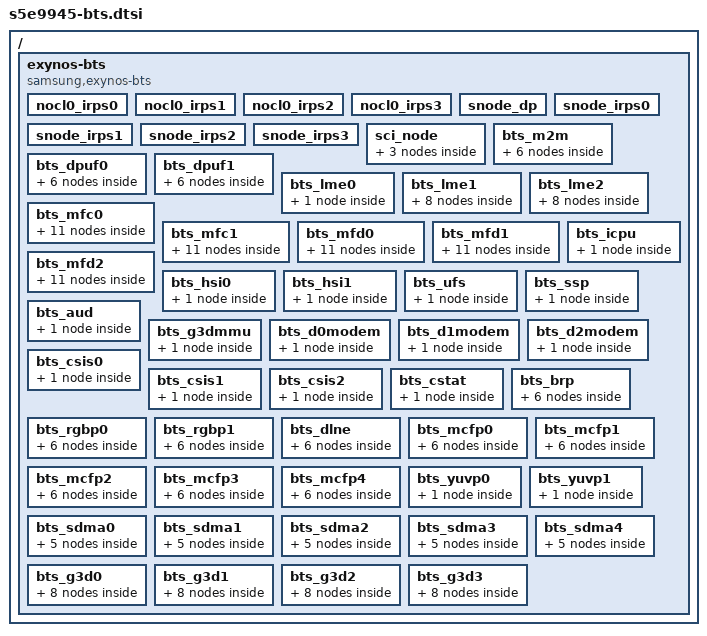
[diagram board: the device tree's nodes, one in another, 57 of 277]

/* SAMSUNG EXYNOS SoC BTS device tree source
 *
 * Copyright (c) 2018 Samsung Electronics Co., Ltd.
 *		http://www.samsung.com
 *
 * SAMSUNG EXYNOS SoC BTS device nodes are listed in this file.
 * EXYNOS based board files should include this file.
 *
 * This program is free software; you can redistribute it and/or modify
 * it under the terms of the GNU General Public License version 2 as
 * published by the Free Software Foundation.
 *
 */

#include <dt-bindings/soc/samsung/exynos-bts.h>

/*
 * TREX_D_NOCL0		0x229E0000
 * TREX_D_NOCL1A	0x238E0000
 * TREX_D_NOCL1B	0x24880000
 * TREX_D_NOCL2A	0x258E0000
 * TREX_D_SDMA		0x213F0000
 * SCI				0x22800000
 * SYSREG_NOCL0		0x22820000
 */

/ {
	exynos-bts {
		compatible = "samsung,exynos-bts";
		acpm-ipc-channel = <8>;
		vch_pd_calid = <0xB1380002>;
		#address-cells = <2>;
		#size-cells = <1>;
		ranges;

		list-scen = "default",
			"cp_throughput",
			"mfc_uhd",
			"mfc_uhd_10bit",
			"mfc_8k_dec30",
			"gdc_8k_8b_30",
			"gdc_8k_8b_60",
			"g3d_heavy",
			"g3d_performance",
			"dp_default",
			"camera_default",
			"npu_normal",
			"mfc_uhd_enc60",
			"camera_heavy",
			"npu_performance";

	        /* num_channel, mif_bus_width, bus_width, mif_util, int_util*/
	        bw_params = <4 16 32 70 70>;

		/* IRPS0/1/2/3 SCI_CTL_SCI_CTRL*/
		nocl0_irps0 {
			#address-cells = <2>;
			#size-cells = <1>;
			ranges;
			reg = <0x0 0x229EA000 0x40>;
			status = "okay";
			bts-type = <TREX_BTS>;
		};
		nocl0_irps1 {
			reg = <0x0 0x229EA040 0x40>;
			status = "okay";
			bts-type = <TREX_BTS>;
		};
		nocl0_irps2 {
			reg = <0x0 0x229EA080 0x40>;
			status = "okay";
			bts-type = <TREX_BTS>;
		};
		nocl0_irps3 {
			reg = <0x0 0x229EA0C0 0x40>;
			status = "okay";
			bts-type = <TREX_BTS>;
		};
		/* QMAX THRESHOLD */
		snode_dp {
			reg = <0x0 0x229EB040 0x8>;
			status = "okay";
			bts-type = <BUSC_BTS>;
		};
		snode_irps0 {
			reg = <0x0 0x229EB000 0x8>;
			status = "okay";
			bts-type = <BUSC_BTS>;
		};
		snode_irps1 {
			reg = <0x0 0x229EB010 0x8>;
			status = "okay";
			bts-type = <BUSC_BTS>;
		};
		snode_irps2 {
			reg = <0x0 0x229EB020 0x8>;
			status = "okay";
			bts-type = <BUSC_BTS>;
		};
		snode_irps3 {
			reg = <0x0 0x229EB030 0x8>;
			status = "okay";
			bts-type = <BUSC_BTS>;
		};
		sci_node {
			reg = <0x0 0x22800100 0x100>;
			status = "okay";
			bts-type = <SCI_BTS>;
			default {
				stat_on = <1>;
				rmo = <0x0>;
				wmo = <0x0>;
				hurrylevel3mo_0 = <0x88>;
				hurrylevel3mo_1 = <0x88>;
			};
			camera_default {
				stat_on = <1>;
				rmo = <0x8>;
				wmo = <0x8>;
				hurrylevel3mo_0 = <0x88>;
				hurrylevel3mo_1 = <0x88>;
			};
			camera_heavy {
				stat_on = <1>;
				rmo = <0x8>;
				wmo = <0x8>;
				hurrylevel3mo_0 = <0x88>;
				hurrylevel3mo_1 = <0x88>;
			};
		};
		/* NOCL1A M2M */
		bts_m2m {
			reg = <0x0 0x238E8000 0x80>;
			status = "okay";
			bts-type = <IP_BTS>;
			default {
				stat_on = <1>;
				bypass = <0>;
				arqos = <0x4>;
				awqos = <0x4>;
				rmo = <0x18>;
				wmo = <0x18>;
				qurgent_on = <0>;
				blocking_on = <1>;
				qmax0_limit_r = <0x8>;
				qmax0_limit_w = <0x8>;
			};
			camera_default {
				stat_on = <1>;
				bypass = <0>;
				arqos = <0x4>;
				awqos = <0x4>;
				rmo = <0x8>;
				wmo = <0x8>;
				qurgent_on = <0>;
				blocking_on = <0>;
			};
			npu_normal {
				stat_on = <1>;
				bypass = <0>;
				arqos = <0x4>;
				awqos = <0x4>;
				rmo = <0x8>;
				wmo = <0x8>;
				qurgent_on = <0>;
				blocking_on = <0>;
			};
			mfc_uhd_enc60 {
				stat_on = <1>;
				bypass = <0>;
				arqos = <0x4>;
				awqos = <0x4>;
				rmo = <0x8>;
				wmo = <0x8>;
				qurgent_on = <0>;
				blocking_on = <0>;
			};
			camera_heavy {
				stat_on = <1>;
				bypass = <0>;
				arqos = <0x4>;
				awqos = <0x4>;
				rmo = <0x20>;
				wmo = <0x20>;
				qurgent_on = <0>;
				blocking_on = <0>;
			};
			npu_performance {
				stat_on = <1>;
				bypass = <0>;
				arqos = <0x4>;
				awqos = <0x4>;
				rmo = <0x8>;
				wmo = <0x8>;
				qurgent_on = <0>;
				blocking_on = <0>;
			};
		};
		/* NOCL1A D0_DPUF0 */
		bts_dpuf0 {
			reg = <0x0 0x238E8080 0x80>;
			status = "okay";
			bts-type = <IP_BTS>;
			default {
				stat_on = <1>;
				bypass = <0>;
				arqos = <0x8>;
				awqos = <0xF>;
				qurgent_on = <0x1>;
				qurgent_th_r = <0x14>;
				blocking_on = <0>;
			};
			camera_default {
				stat_on = <1>;
				bypass = <0>;
				arqos = <0x8>;
				awqos = <0xF>;
				rmo = <0x30>;
				wmo = <0x30>;
				qurgent_on = <0x1>;
				qurgent_th_r = <0x14>;
				blocking_on = <0>;
			};
			npu_normal {
				stat_on = <1>;
				bypass = <0>;
				arqos = <0x8>;
				awqos = <0xF>;
				rmo = <0x30>;
				wmo = <0x30>;
				qurgent_on = <0x1>;
				qurgent_th_r = <0x14>;
				blocking_on = <0>;
			};
			mfc_uhd_enc60 {
				stat_on = <1>;
				bypass = <0>;
				arqos = <0x8>;
				awqos = <0xF>;
				rmo = <0x20>;
				wmo = <0x20>;
				qurgent_on = <0>;
				blocking_on = <0>;
			};
			camera_heavy {
				stat_on = <1>;
				bypass = <0>;
				arqos = <0x8>;
				awqos = <0xF>;
				rmo = <0x30>;
				wmo = <0x30>;
				qurgent_on = <0x1>;
				qurgent_th_r = <0x14>;
				blocking_on = <0>;
			};
			npu_performance {
				stat_on = <1>;
				bypass = <0>;
				arqos = <0x8>;
				awqos = <0xF>;
				rmo = <0x20>;
				wmo = <0x20>;
				qurgent_on = <0>;
				blocking_on = <0>;
			};
		};
		/* NOCL1A D1_DPUF0 */
		bts_dpuf1 {
			reg = <0x0 0x238E8100 0x80>;
			status = "okay";
			bts-type = <IP_BTS>;
			default {
				stat_on = <1>;
				bypass = <0>;
				arqos = <0x8>;
				awqos = <0xF>;
				qurgent_on = <0x1>;
				qurgent_th_r = <0x14>;
				blocking_on = <0>;
			};
			camera_default {
				stat_on = <1>;
				bypass = <0>;
				arqos = <0x8>;
				awqos = <0xF>;
				rmo = <0x30>;
				wmo = <0x30>;
				qurgent_on = <0x1>;
				qurgent_th_r = <0x14>;
				blocking_on = <0>;
			};
			npu_normal {
				stat_on = <1>;
				bypass = <0>;
				arqos = <0x8>;
				awqos = <0xF>;
				rmo = <0x30>;
				wmo = <0x30>;
				qurgent_on = <0x1>;
				qurgent_th_r = <0x14>;
				blocking_on = <0>;
			};
			mfc_uhd_enc60 {
				stat_on = <1>;
				bypass = <0>;
				arqos = <0x8>;
				awqos = <0xF>;
				rmo = <0x20>;
				wmo = <0x20>;
				qurgent_on = <0>;
				blocking_on = <0>;
			};
			camera_heavy {
				stat_on = <1>;
				bypass = <0>;
				arqos = <0x8>;
				awqos = <0xF>;
				rmo = <0x30>;
				wmo = <0x30>;
				qurgent_on = <0x1>;
				qurgent_th_r = <0x14>;
				blocking_on = <0>;
			};
			npu_performance {
				stat_on = <1>;
				bypass = <0>;
				arqos = <0x8>;
				awqos = <0xF>;
				rmo = <0x20>;
				wmo = <0x20>;
				qurgent_on = <0>;
				blocking_on = <0>;
			};
		};
		/* NOCL1A D0LME */
		bts_lme0 {
			reg = <0x0 0x238E8180 0x80>;
			status = "okay";
			bts-type = <IP_BTS>;
			default {
				stat_on = <1>;
				bypass = <0>;
				arqos = <0x4>;
				awqos = <0x4>;
				rmo = <0x14>;
				wmo = <0x10>;
				qurgent_on = <0>;
				blocking_on = <0>;
			};
		};
		/* NOCL1A D1LME */
		bts_lme1 {
			reg = <0x0 0x238E8200 0x80>;
			status = "okay";
			bts-type = <IP_BTS>;
			default {
				stat_on = <1>;
				bypass = <0>;
				arqos = <0x4>;
				awqos = <0x4>;
				rmo = <0x4>;
				wmo = <0x8>;
				qurgent_on = <0>;
				blocking_on = <0>;
			};
			gdc_8k_8b_30 {
				stat_on = <1>;
				bypass = <0>;
				arqos = <0x4>;
				awqos = <0x4>;
				rmo = <0x3C>;
				wmo = <0x14>;
				qurgent_on = <0>;
				blocking_on = <0>;
			};
			gdc_8k_8b_60 {
				stat_on = <1>;
				bypass = <0>;
				arqos = <0x4>;
				awqos = <0x4>;
				rmo = <0x84>;
				wmo = <0x28>;
				qurgent_on = <0>;
				blocking_on = <0>;
			};
			camera_default {
				stat_on = <1>;
				bypass = <0>;
				arqos = <0x4>;
				awqos = <0x4>;
				rmo = <0x14>;
				wmo = <0x8>;
				qurgent_on = <0>;
				blocking_on = <0>;
			};
			npu_normal {
				stat_on = <1>;
				bypass = <0>;
				arqos = <0x4>;
				awqos = <0x4>;
				rmo = <0x14>;
				wmo = <0x8>;
				qurgent_on = <0>;
				blocking_on = <0>;
			};
			mfc_uhd_enc60 {
				stat_on = <1>;
				bypass = <0>;
				arqos = <0x4>;
				awqos = <0x4>;
				rmo = <0x14>;
				wmo = <0x8>;
				qurgent_on = <0>;
				blocking_on = <0>;
			};
			camera_heavy {
				stat_on = <1>;
				bypass = <0>;
				arqos = <0x4>;
				awqos = <0x4>;
				rmo = <0x28>;
				wmo = <0x10>;
				qurgent_on = <0>;
				blocking_on = <0>;
			};
			npu_performance {
				stat_on = <1>;
				bypass = <0>;
				arqos = <0x4>;
				awqos = <0x4>;
				rmo = <0x4>;
				wmo = <0x8>;
				qurgent_on = <0>;
				blocking_on = <0>;
			};
		};
		/* NOCL1A D2LME */
		bts_lme2 {
			reg = <0x0 0x238E8280 0x80>;
			status = "okay";
			bts-type = <IP_BTS>;
			default {
				stat_on = <1>;
				bypass = <0>;
				arqos = <0x4>;
				awqos = <0x4>;
				rmo = <0xC>;
				wmo = <0xC>;
				qurgent_on = <0>;
				blocking_on = <0>;
			};
			gdc_8k_8b_30 {
				stat_on = <1>;
				bypass = <0>;
				arqos = <0x4>;
				awqos = <0x4>;
				rmo = <0xC>;
				wmo = <0xC>;
				qurgent_on = <0>;
				blocking_on = <0>;
			};
			gdc_8k_8b_60 {
				stat_on = <1>;
				bypass = <0>;
				arqos = <0x4>;
				awqos = <0x4>;
				rmo = <0xC>;
				wmo = <0xC>;
				qurgent_on = <0>;
				blocking_on = <0>;
			};
			camera_default {
				stat_on = <1>;
				bypass = <0>;
				arqos = <0x4>;
				awqos = <0x4>;
				rmo = <0xC>;
				wmo = <0xC>;
				qurgent_on = <0>;
				blocking_on = <0>;
			};
			npu_normal {
				stat_on = <1>;
				bypass = <0>;
				arqos = <0x4>;
				awqos = <0x4>;
				rmo = <0xC>;
				wmo = <0xC>;
				qurgent_on = <0>;
				blocking_on = <0>;
			};
			mfc_uhd_enc60 {
				stat_on = <1>;
				bypass = <0>;
				arqos = <0x4>;
				awqos = <0x4>;
				rmo = <0xC>;
				wmo = <0xC>;
				qurgent_on = <0>;
				blocking_on = <0>;
			};
			camera_heavy {
				stat_on = <1>;
				bypass = <0>;
				arqos = <0x4>;
				awqos = <0x4>;
				rmo = <0xE>;
				wmo = <0xE>;
				qurgent_on = <0>;
				blocking_on = <0>;
			};
			npu_performance {
				stat_on = <1>;
				bypass = <0>;
				arqos = <0x4>;
				awqos = <0x4>;
				rmo = <0xC>;
				wmo = <0xC>;
				qurgent_on = <0>;
				blocking_on = <0>;
			};
		};
		/* NOCL1B D0_MFC */
		bts_mfc0 {
			reg = <0x0 0x24888000 0x80>;
			status = "okay";
			bts-type = <IP_BTS>;
			default {
				stat_on = <1>;
				bypass = <0>;
				arqos = <0x4>;
				awqos = <0x4>;
				rmo = <0x1C>;
				wmo = <0xC>;
				qurgent_on = <0>;
				blocking_on = <0>;
			};
			mfc_uhd {
				stat_on = <1>;
				bypass = <0>;
				arqos = <0x4>;
				awqos = <0x4>;
				rmo = <0x20>;
				wmo = <0x20>;
				qurgent_on = <0>;
				blocking_on = <0>;
			};
			mfc_uhd_10bit {
				stat_on = <1>;
				bypass = <0>;
				arqos = <0x4>;
				awqos = <0x4>;
				rmo = <0x20>;
				wmo = <0x20>;
				qurgent_on = <0>;
				blocking_on = <0>;
			};
			mfc_8k_dec30 {
				stat_on = <1>;
				bypass = <0>;
				arqos = <0x4>;
				awqos = <0x4>;
				rmo = <0x40>;
				wmo = <0x40>;
				qurgent_on = <0>;
				blocking_on = <0>;
			};
			g3d_performance {
				stat_on = <1>;
				bypass = <0>;
				arqos = <0x4>;
				awqos = <0x4>;
				rmo = <0x20>;
				wmo = <0x20>;
				qurgent_on = <0>;
				blocking_on = <0>;
			};
			dp_default {
				stat_on = <1>;
				bypass = <0>;
				arqos = <0x4>;
				awqos = <0x4>;
				rmo = <0x20>;
				wmo = <0x20>;
				qurgent_on = <0>;
				blocking_on = <0>;
			};
			camera_default {
				stat_on = <1>;
				bypass = <0>;
				arqos = <0x4>;
				awqos = <0x4>;
				rmo = <0x1C>;
				wmo = <0xC>;
				qurgent_on = <0>;
				blocking_on = <0>;
			};
			npu_normal {
				stat_on = <1>;
				bypass = <0>;
				arqos = <0x4>;
				awqos = <0x4>;
				rmo = <0x1C>;
				wmo = <0xC>;
				qurgent_on = <0>;
				blocking_on = <0>;
			};
			mfc_uhd_enc60 {
				stat_on = <1>;
				bypass = <0>;
				arqos = <0x4>;
				awqos = <0x4>;
				rmo = <0x20>;
				wmo = <0x20>;
				qurgent_on = <0>;
				blocking_on = <0>;
			};
			camera_heavy {
				stat_on = <1>;
				bypass = <0>;
				arqos = <0x4>;
				awqos = <0x4>;
				rmo = <0x1C>;
				wmo = <0xC>;
				qurgent_on = <0>;
				blocking_on = <0>;
			};
			npu_performance {
				stat_on = <1>;
				bypass = <0>;
				arqos = <0x4>;
				awqos = <0x4>;
				rmo = <0x1C>;
				wmo = <0xC>;
				qurgent_on = <0>;
				blocking_on = <0>;
			};
		};
		/* NOCL1B D1_MFC */
		bts_mfc1 {
			reg = <0x0 0x24888080 0x80>;
			status = "okay";
			bts-type = <IP_BTS>;
			default {
				stat_on = <1>;
				bypass = <0>;
				arqos = <0x4>;
				awqos = <0x4>;
				rmo = <0x1C>;
				wmo = <0xC>;
				qurgent_on = <0>;
				blocking_on = <0>;
			};
			mfc_uhd {
				stat_on = <1>;
				bypass = <0>;
				arqos = <0x4>;
				awqos = <0x4>;
				rmo = <0x20>;
				wmo = <0x20>;
				qurgent_on = <0>;
				blocking_on = <0>;
			};
			mfc_uhd_10bit {
				stat_on = <1>;
				bypass = <0>;
				arqos = <0x4>;
				awqos = <0x4>;
				rmo = <0x20>;
				wmo = <0x20>;
				qurgent_on = <0>;
				blocking_on = <0>;
			};
			mfc_8k_dec30 {
				stat_on = <1>;
				bypass = <0>;
				arqos = <0x4>;
				awqos = <0x4>;
				rmo = <0x40>;
				wmo = <0x40>;
				qurgent_on = <0>;
				blocking_on = <0>;
			};
			g3d_performance {
				stat_on = <1>;
				bypass = <0>;
				arqos = <0x4>;
				awqos = <0x4>;
				rmo = <0x20>;
				wmo = <0x20>;
				qurgent_on = <0>;
				blocking_on = <0>;
			};
			dp_default {
				stat_on = <1>;
				bypass = <0>;
				arqos = <0x4>;
				awqos = <0x4>;
				rmo = <0x20>;
				wmo = <0x20>;
				qurgent_on = <0>;
				blocking_on = <0>;
			};
			camera_default {
				stat_on = <1>;
				bypass = <0>;
				arqos = <0x4>;
				awqos = <0x4>;
				rmo = <0x1C>;
				wmo = <0xC>;
				qurgent_on = <0>;
				blocking_on = <0>;
			};
			npu_normal {
				stat_on = <1>;
				bypass = <0>;
				arqos = <0x4>;
				awqos = <0x4>;
				rmo = <0x1C>;
				wmo = <0xC>;
				qurgent_on = <0>;
				blocking_on = <0>;
			};
			mfc_uhd_enc60 {
				stat_on = <1>;
				bypass = <0>;
				arqos = <0x4>;
				awqos = <0x4>;
				rmo = <0x20>;
				wmo = <0x20>;
				qurgent_on = <0>;
				blocking_on = <0>;
			};
			camera_heavy {
				stat_on = <1>;
				bypass = <0>;
				arqos = <0x4>;
				awqos = <0x4>;
				rmo = <0x1C>;
				wmo = <0xC>;
				qurgent_on = <0>;
				blocking_on = <0>;
			};
			npu_performance {
				stat_on = <1>;
				bypass = <0>;
				arqos = <0x4>;
				awqos = <0x4>;
				rmo = <0x1C>;
				wmo = <0xC>;
				qurgent_on = <0>;
				blocking_on = <0>;
			};
		};
		/* NOCL1B D0_MFD */
		bts_mfd0 {
			reg = <0x0 0x24888100 0x80>;
			status = "okay";
			bts-type = <IP_BTS>;
			default {
				stat_on = <1>;
				bypass = <0>;
				arqos = <0x4>;
				awqos = <0x4>;
				rmo = <0x1C>;
				wmo = <0xC>;
				qurgent_on = <0>;
				blocking_on = <0>;
			};
			mfc_uhd {
				stat_on = <1>;
				bypass = <0>;
				arqos = <0x4>;
				awqos = <0x4>;
				rmo = <0x20>;
				wmo = <0x20>;
				qurgent_on = <0>;
				blocking_on = <0>;
			};
			mfc_uhd_10bit {
				stat_on = <1>;
				bypass = <0>;
				arqos = <0x4>;
				awqos = <0x4>;
				rmo = <0x20>;
				wmo = <0x20>;
				qurgent_on = <0>;
				blocking_on = <0>;
			};
			mfc_8k_dec30 {
				stat_on = <1>;
				bypass = <0>;
				arqos = <0x4>;
				awqos = <0x4>;
				rmo = <0x40>;
				wmo = <0x40>;
				qurgent_on = <0>;
				blocking_on = <0>;
			};
			g3d_performance {
				stat_on = <1>;
				bypass = <0>;
				arqos = <0x4>;
				awqos = <0x4>;
				rmo = <0x20>;
				wmo = <0x20>;
				qurgent_on = <0>;
				blocking_on = <0>;
			};
			dp_default {
				stat_on = <1>;
				bypass = <0>;
				arqos = <0x4>;
				awqos = <0x4>;
				rmo = <0x20>;
				wmo = <0x20>;
				qurgent_on = <0>;
				blocking_on = <0>;
			};
			camera_default {
				stat_on = <1>;
				bypass = <0>;
				arqos = <0x4>;
				awqos = <0x4>;
				rmo = <0x1C>;
				wmo = <0xC>;
				qurgent_on = <0>;
				blocking_on = <0>;
			};
			npu_normal {
				stat_on = <1>;
				bypass = <0>;
				arqos = <0x4>;
				awqos = <0x4>;
				rmo = <0x1C>;
				wmo = <0xC>;
				qurgent_on = <0>;
				blocking_on = <0>;
			};
			mfc_uhd_enc60 {
				stat_on = <1>;
				bypass = <0>;
				arqos = <0x4>;
				awqos = <0x4>;
				rmo = <0x20>;
				wmo = <0x20>;
				qurgent_on = <0>;
				blocking_on = <0>;
			};
			camera_heavy {
				stat_on = <1>;
				bypass = <0>;
				arqos = <0x4>;
				awqos = <0x4>;
				rmo = <0x1C>;
				wmo = <0xC>;
				qurgent_on = <0>;
				blocking_on = <0>;
			};
			npu_performance {
				stat_on = <1>;
				bypass = <0>;
				arqos = <0x4>;
				awqos = <0x4>;
				rmo = <0x20>;
				wmo = <0x20>;
				qurgent_on = <0>;
				blocking_on = <0>;
			};
		};
		/* NOCL1B D1_MFD */
		bts_mfd1 {
			reg = <0x0 0x24888180 0x80>;
			status = "okay";
			bts-type = <IP_BTS>;
			default {
				stat_on = <1>;
				bypass = <0>;
				arqos = <0x4>;
				awqos = <0x4>;
				rmo = <0x1C>;
				wmo = <0xC>;
				qurgent_on = <0>;
				blocking_on = <0>;
			};
			mfc_uhd {
				stat_on = <1>;
				bypass = <0>;
				arqos = <0x4>;
				awqos = <0x4>;
				rmo = <0x20>;
				wmo = <0x20>;
				qurgent_on = <0>;
				blocking_on = <0>;
			};
			mfc_uhd_10bit {
				stat_on = <1>;
				bypass = <0>;
				arqos = <0x4>;
				awqos = <0x4>;
				rmo = <0x20>;
				wmo = <0x20>;
				qurgent_on = <0>;
				blocking_on = <0>;
			};
			mfc_8k_dec30 {
				stat_on = <1>;
				bypass = <0>;
				arqos = <0x4>;
				awqos = <0x4>;
				rmo = <0x40>;
				wmo = <0x40>;
				qurgent_on = <0>;
				blocking_on = <0>;
			};
			g3d_performance {
				stat_on = <1>;
				bypass = <0>;
				arqos = <0x4>;
				awqos = <0x4>;
				rmo = <0x20>;
				wmo = <0x20>;
				qurgent_on = <0>;
				blocking_on = <0>;
			};
			dp_default {
				stat_on = <1>;
				bypass = <0>;
				arqos = <0x4>;
				awqos = <0x4>;
				rmo = <0x20>;
				wmo = <0x20>;
				qurgent_on = <0>;
				blocking_on = <0>;
			};
			camera_default {
				stat_on = <1>;
				bypass = <0>;
				arqos = <0x4>;
				awqos = <0x4>;
				rmo = <0x1C>;
				wmo = <0xC>;
				qurgent_on = <0>;
				blocking_on = <0>;
			};
			npu_normal {
				stat_on = <1>;
				bypass = <0>;
				arqos = <0x4>;
				awqos = <0x4>;
				rmo = <0x1C>;
				wmo = <0xC>;
				qurgent_on = <0>;
				blocking_on = <0>;
			};
			mfc_uhd_enc60 {
				stat_on = <1>;
				bypass = <0>;
				arqos = <0x4>;
				awqos = <0x4>;
				rmo = <0x20>;
				wmo = <0x20>;
				qurgent_on = <0>;
				blocking_on = <0>;
			};
			camera_heavy {
				stat_on = <1>;
				bypass = <0>;
				arqos = <0x4>;
				awqos = <0x4>;
				rmo = <0x1C>;
				wmo = <0xC>;
				qurgent_on = <0>;
				blocking_on = <0>;
			};
			npu_performance {
				stat_on = <1>;
				bypass = <0>;
				arqos = <0x4>;
				awqos = <0x4>;
				rmo = <0x1C>;
				wmo = <0xC>;
				qurgent_on = <0>;
				blocking_on = <0>;
			};
		};
		/* NOCL1B D2_MFD */
		bts_mfd2 {
			reg = <0x0 0x24888200 0x80>;
			status = "okay";
			bts-type = <IP_BTS>;
			default {
				stat_on = <1>;
				bypass = <0>;
				arqos = <0x4>;
				awqos = <0x4>;
				rmo = <0x1C>;
				wmo = <0xC>;
				qurgent_on = <0>;
				blocking_on = <0>;
			};
			mfc_uhd {
				stat_on = <1>;
				bypass = <0>;
				arqos = <0x4>;
				awqos = <0x4>;
				rmo = <0x20>;
				wmo = <0x20>;
				qurgent_on = <0>;
				blocking_on = <0>;
			};
			mfc_uhd_10bit {
				stat_on = <1>;
				bypass = <0>;
				arqos = <0x4>;
				awqos = <0x4>;
				rmo = <0x20>;
				wmo = <0x20>;
				qurgent_on = <0>;
				blocking_on = <0>;
			};
			mfc_8k_dec30 {
				stat_on = <1>;
				bypass = <0>;
				arqos = <0x4>;
				awqos = <0x4>;
				rmo = <0x40>;
				wmo = <0x40>;
				qurgent_on = <0>;
				blocking_on = <0>;
			};
			g3d_performance {
				stat_on = <1>;
				bypass = <0>;
				arqos = <0x4>;
				awqos = <0x4>;
				rmo = <0x20>;
				wmo = <0x20>;
				qurgent_on = <0>;
				blocking_on = <0>;
			};
			dp_default {
				stat_on = <1>;
				bypass = <0>;
				arqos = <0x4>;
				awqos = <0x4>;
				rmo = <0x20>;
				wmo = <0x20>;
				qurgent_on = <0>;
				blocking_on = <0>;
			};
			camera_default {
				stat_on = <1>;
				bypass = <0>;
				arqos = <0x4>;
				awqos = <0x4>;
				rmo = <0x1C>;
				wmo = <0xC>;
				qurgent_on = <0>;
				blocking_on = <0>;
			};
			npu_normal {
				stat_on = <1>;
				bypass = <0>;
				arqos = <0x4>;
				awqos = <0x4>;
				rmo = <0x1C>;
				wmo = <0xC>;
				qurgent_on = <0>;
				blocking_on = <0>;
			};
			mfc_uhd_enc60 {
				stat_on = <1>;
				bypass = <0>;
				arqos = <0x4>;
				awqos = <0x4>;
				rmo = <0x20>;
				wmo = <0x20>;
				qurgent_on = <0>;
				blocking_on = <0>;
			};
			camera_heavy {
				stat_on = <1>;
				bypass = <0>;
				arqos = <0x4>;
				awqos = <0x4>;
				rmo = <0x1C>;
				wmo = <0xC>;
				qurgent_on = <0>;
				blocking_on = <0>;
			};
			npu_performance {
				stat_on = <1>;
				bypass = <0>;
				arqos = <0x4>;
				awqos = <0x4>;
				rmo = <0x1C>;
				wmo = <0xC>;
				qurgent_on = <0>;
				blocking_on = <0>;
			};
		};
		/* NOCL1B ICPU */
		bts_icpu {
			reg = <0x0 0x24888280 0x80>;
			status = "okay";
			bts-type = <IP_BTS>;
			cal-pdid = <0xB1380002>;
			default {
				stat_on = <1>;
				bypass = <0>;
				arqos = <0x4>;
				awqos = <0x4>;
				rmo = <0xFFFF>;
				wmo = <0xFFFF>;
				qurgent_on = <0>;
				blocking_on = <0>;
			};
		};
		/* NOCL1B HSI0 */
		bts_hsi0 {
			reg = <0x0 0x24888300 0x80>;
			status = "okay";
			bts-type = <IP_BTS>;
			default {
				stat_on = <1>;
				bypass = <0>;
				arqos = <0x4>;
				awqos = <0x4>;
				rmo = <0x4>;
				wmo = <0x4>;
				qurgent_on = <0>;
				blocking_on = <1>;
				qmax0_limit_r = <0x1>;
				qmax0_limit_w = <0x1>;
			};
		};
		/* NOCL1B HSI1 */
		bts_hsi1 {
			reg = <0x0 0x24888380 0x80>;
			status = "okay";
			bts-type = <IP_BTS>;
			default {
				stat_on = <1>;
				bypass = <0>;
				arqos = <0x4>;
				awqos = <0x4>;
				rmo = <0x8>;
				wmo = <0x8>;
				qurgent_on = <0>;
				blocking_on = <1>;
				qmax0_limit_r = <0x1>;
				qmax0_limit_w = <0x1>;
			};
		};
		/* NOCL1B ufs */
		bts_ufs {
			reg = <0x0 0x24888400 0x80>;
			status = "okay";
			bts-type = <IP_BTS>;
			default {
				stat_on = <1>;
				bypass = <0>;
				arqos = <0x4>;
				awqos = <0x4>;
				rmo = <0x10>;
				wmo = <0xC>;
				qurgent_on = <0>;
				blocking_on = <1>;
				qmax0_limit_r = <0x1>;
				qmax0_limit_w = <0x1>;
			};
		};
		/* NOCL1B SSP */
		bts_ssp {
			reg = <0x0 0x24888480 0x80>;
			status = "okay";
			bts-type = <IP_BTS>;
			default {
				stat_on = <1>;
				bypass = <0>;
				arqos = <0x4>;
				awqos = <0x4>;
				rmo = <0x4>;
				wmo = <0x4>;
				qurgent_on = <0>;
				blocking_on = <0>;
			};
		};
		/* NOCL1A AUD */
		bts_aud {
			reg = <0x0 0x238E8300 0x80>;
			status = "okay";
			bts-type = <IP_BTS>;
			default {
				stat_on = <1>;
				bypass = <0>;
				arqos = <0xC>;
				awqos = <0xF>;
				qurgent_on = <0x1>;
				qurgent_th_r = <0x14>;
				qurgent_th_w = <0x14>;
				blocking_on = <0>;
			};
		};
		/* NOCL0 MMUCS */
		bts_g3dmmu {
			reg = <0x0 0x229E8200 0x80>;
			status = "okay";
			bts-type = <IP_BTS>;
			default {
				stat_on = <1>;
				bypass = <0>;
				arqos = <0x4>;
				awqos = <0x4>;
				rmo = <0x4>;
				wmo = <0x4>;
				qurgent_on = <0>;
				blocking_on = <0>;
			};
		};
		/* NOCL0 D0_MODEM */
		bts_d0modem {
			reg = <0x0 0x229E8000 0x80>;
			status = "okay";
			bts-type = <IP_BTS>;
			default {
				stat_on = <1>;
				bypass = <0>;
				arqos = <0xC>;
				awqos = <0xF>;
				rmo = <0x20>;
				wmo = <0x20>;
				qurgent_on = <0x1>;
				qurgent_th_r = <0x14>;
				qurgent_th_w = <0x14>;
				blocking_on = <0>;
			};
		};
		/* NOCL0 D1_MODEM */
		bts_d1modem {
			reg = <0x0 0x229E8080 0x80>;
			status = "okay";
			bts-type = <IP_BTS>;
			default {
				stat_on = <1>;
				bypass = <1>;
				rmo = <0x14>;
				wmo = <0x14>;
				qurgent_on = <0>;
				blocking_on = <0>;
			};
		};
		/* NOCL0 D2_MODEM */
		bts_d2modem {
			reg = <0x0 0x229E8100 0x80>;
			status = "okay";
			bts-type = <IP_BTS>;
			default {
				stat_on = <1>;
				bypass = <0>;
				arqos = <0x4>;
				awqos = <0x4>;
				rmo = <0x14>;
				wmo = <0x8>;
				qurgent_on = <0>;
				blocking_on = <0>;
			};
		};
		/* NOCL2A D0_CSIS */
		bts_csis0 {
			reg = <0x0 0x258E8000 0x80>;
			status = "okay";
			bts-type = <IP_BTS>;
			cal-pdid = <0xB1380002>;
			default {
				stat_on = <1>;
				bypass = <0>;
				arqos = <0xC>;
				awqos = <0xF>;
				qurgent_on = <0x1>;
				qurgent_ex = <0>;
				qurgent_th_r = <0x14>;
				qurgent_th_w = <0xD>;
				blocking_on = <0>;
			};
		};
		/* NOCL2A D1_CSIS */
		bts_csis1 {
			reg = <0x0 0x258E8080 0x80>;
			status = "okay";
			bts-type = <IP_BTS>;
			cal-pdid = <0xB1380002>;
			default {
				stat_on = <1>;
				bypass = <0>;
				arqos = <0xC>;
				awqos = <0xF>;
				qurgent_on = <0x1>;
				qurgent_ex = <0>;
				qurgent_th_r = <0x14>;
				qurgent_th_w = <0xD>;
				blocking_on = <0>;
			};
		};
		/* NOCL2A D2_CSIS */
		bts_csis2 {
			reg = <0x0 0x258E8100 0x80>;
			status = "okay";
			bts-type = <IP_BTS>;
			cal-pdid = <0xB1380002>;
			default {
				stat_on = <1>;
				bypass = <0>;
				arqos = <0xC>;
				awqos = <0xF>;
				qurgent_on = <0x1>;
				qurgent_ex = <0>;
				qurgent_th_r = <0x14>;
				qurgent_th_w = <0xD>;
				blocking_on = <0>;
			};
		};
		/* NOCL2A CSTAT */
		bts_cstat {
			reg = <0x0 0x258E8180 0x80>;
			status = "okay";
			bts-type = <IP_BTS>;
			cal-pdid = <0xB1380002>;
			default {
				stat_on = <1>;
				bypass = <0>;
				arqos = <0xC>;
				awqos = <0xF>;
				qurgent_on = <0x1>;
				qurgent_th_r = <0x14>;
				qurgent_th_w = <0xD>;
				blocking_on = <0>;
			};
		};
		/* NOCL2A BRP */
		bts_brp {
			reg = <0x0 0x258E8200 0x80>;
			status = "okay";
			bts-type = <IP_BTS>;
			cal-pdid = <0xB1380002>;
			default {
				stat_on = <1>;
				bypass = <0>;
				arqos = <0x4>;
				awqos = <0x4>;
				rmo = <0x4>;
				wmo = <0x8>;
				qurgent_on = <0>;
				blocking_on = <0>;
			};
			camera_default {
				stat_on = <1>;
				bypass = <0>;
				arqos = <0x4>;
				awqos = <0x4>;
				rmo = <0x10>;
				wmo = <0x8>;
				qurgent_on = <0>;
				blocking_on = <0>;
			};
			npu_normal {
				stat_on = <1>;
				bypass = <0>;
				arqos = <0x4>;
				awqos = <0x4>;
				rmo = <0x10>;
				wmo = <0x8>;
				qurgent_on = <0>;
				blocking_on = <0>;
			};
			mfc_uhd_enc60 {
				stat_on = <1>;
				bypass = <0>;
				arqos = <0x4>;
				awqos = <0x4>;
				rmo = <0x4>;
				wmo = <0x8>;
				qurgent_on = <0>;
				blocking_on = <0>;
			};
			camera_heavy {
				stat_on = <1>;
				bypass = <0>;
				arqos = <0x4>;
				awqos = <0x4>;
				rmo = <0x20>;
				wmo = <0x20>;
				qurgent_on = <0>;
				blocking_on = <0>;
			};
			npu_performance {
				stat_on = <1>;
				bypass = <0>;
				arqos = <0x4>;
				awqos = <0x4>;
				rmo = <0x4>;
				wmo = <0x8>;
				qurgent_on = <0>;
				blocking_on = <0>;
			};

		};
		/* NOCL2A D0_RGBP */
		bts_rgbp0 {
			reg = <0x0 0x258E8280 0x80>;
			status = "okay";
			bts-type = <IP_BTS>;
			cal-pdid = <0xB1380002>;
			default {
				stat_on = <1>;
				bypass = <0>;
				arqos = <0x4>;
				awqos = <0x4>;
				rmo = <0x4>;
				wmo = <0x8>;
				qurgent_on = <0>;
				blocking_on = <0>;
			};
			camera_default {
				stat_on = <1>;
				bypass = <0>;
				arqos = <0x4>;
				awqos = <0x4>;
				rmo = <0x10>;
				wmo = <0x8>;
				qurgent_on = <0>;
				blocking_on = <0>;
			};
			npu_normal {
				stat_on = <1>;
				bypass = <0>;
				arqos = <0x4>;
				awqos = <0x4>;
				rmo = <0x10>;
				wmo = <0x8>;
				qurgent_on = <0>;
				blocking_on = <0>;
			};
			mfc_uhd_enc60 {
				stat_on = <1>;
				bypass = <0>;
				arqos = <0x4>;
				awqos = <0x4>;
				rmo = <0x4>;
				wmo = <0x8>;
				qurgent_on = <0>;
				blocking_on = <0>;
			};
			camera_heavy {
				stat_on = <1>;
				bypass = <0>;
				arqos = <0x4>;
				awqos = <0x4>;
				rmo = <0x20>;
				wmo = <0x20>;
				qurgent_on = <0>;
				blocking_on = <0>;
			};
			npu_performance {
				stat_on = <1>;
				bypass = <0>;
				arqos = <0x4>;
				awqos = <0x4>;
				rmo = <0x4>;
				wmo = <0x8>;
				qurgent_on = <0>;
				blocking_on = <0>;
			};

		};
		/* NOCL2A D1_RGBP */
		bts_rgbp1 {
			reg = <0x0 0x258E8300 0x80>;
			status = "okay";
			bts-type = <IP_BTS>;
			cal-pdid = <0xB1380002>;
			default {
				stat_on = <1>;
				bypass = <0>;
				arqos = <0x4>;
				awqos = <0x4>;
				rmo = <0x4>;
				wmo = <0x8>;
				qurgent_on = <0>;
				blocking_on = <0>;
			};
			camera_default {
				stat_on = <1>;
				bypass = <0>;
				arqos = <0x4>;
				awqos = <0x4>;
				rmo = <0x10>;
				wmo = <0x8>;
				qurgent_on = <0>;
				blocking_on = <0>;
			};
			npu_normal {
				stat_on = <1>;
				bypass = <0>;
				arqos = <0x4>;
				awqos = <0x4>;
				rmo = <0x10>;
				wmo = <0x8>;
				qurgent_on = <0>;
				blocking_on = <0>;
			};
			mfc_uhd_enc60 {
				stat_on = <1>;
				bypass = <0>;
				arqos = <0x4>;
				awqos = <0x4>;
				rmo = <0x4>;
				wmo = <0x8>;
				qurgent_on = <0>;
				blocking_on = <0>;
			};
			camera_heavy {
				stat_on = <1>;
				bypass = <0>;
				arqos = <0x4>;
				awqos = <0x4>;
				rmo = <0x20>;
				wmo = <0x20>;
				qurgent_on = <0>;
				blocking_on = <0>;
			};
			npu_performance {
				stat_on = <1>;
				bypass = <0>;
				arqos = <0x4>;
				awqos = <0x4>;
				rmo = <0x4>;
				wmo = <0x8>;
				qurgent_on = <0>;
				blocking_on = <0>;
			};

		};
		/* NOCL2A D_DLNE */
		bts_dlne {
			reg = <0x0 0x258E8380 0x80>;
			status = "okay";
			bts-type = <IP_BTS>;
			cal-pdid = <0xB1380002>;
			default {
				stat_on = <1>;
				bypass = <0>;
				arqos = <0x4>;
				awqos = <0x4>;
				rmo = <0x8>;
				wmo = <0x8>;
				qurgent_on = <0>;
				blocking_on = <0>;
			};
			camera_default {
				stat_on = <1>;
				bypass = <0>;
				arqos = <0x4>;
				awqos = <0x4>;
				rmo = <0x10>;
				wmo = <0x8>;
				qurgent_on = <0>;
				blocking_on = <0>;
			};
			npu_normal {
				stat_on = <1>;
				bypass = <0>;
				arqos = <0x4>;
				awqos = <0x4>;
				rmo = <0x10>;
				wmo = <0x8>;
				qurgent_on = <0>;
				blocking_on = <0>;
			};
			mfc_uhd_enc60 {
				stat_on = <1>;
				bypass = <0>;
				arqos = <0x4>;
				awqos = <0x4>;
				rmo = <0x8>;
				wmo = <0x8>;
				qurgent_on = <0>;
				blocking_on = <0>;
			};
			camera_heavy {
				stat_on = <1>;
				bypass = <0>;
				arqos = <0x4>;
				awqos = <0x4>;
				rmo = <0x20>;
				wmo = <0x20>;
				qurgent_on = <0>;
				blocking_on = <0>;
			};
			npu_performance {
				stat_on = <1>;
				bypass = <0>;
				arqos = <0x4>;
				awqos = <0x4>;
				rmo = <0x8>;
				wmo = <0x8>;
				qurgent_on = <0>;
				blocking_on = <0>;
			};
		};
		/* NOCL2A D0_MCFP */
		bts_mcfp0 {
			reg = <0x0 0x258E8400 0x80>;
			status = "okay";
			bts-type = <IP_BTS>;
			cal-pdid = <0xB1380002>;
			default {
				stat_on = <1>;
				bypass = <0>;
				arqos = <0x4>;
				awqos = <0x4>;
				rmo = <0x8>;
				wmo = <0x8>;
				qurgent_on = <0>;
				blocking_on = <0>;
			};
			camera_default {
				stat_on = <1>;
				bypass = <0>;
				arqos = <0x4>;
				awqos = <0x4>;
				rmo = <0x10>;
				wmo = <0x8>;
				qurgent_on = <0>;
				blocking_on = <0>;
			};
			npu_normal {
				stat_on = <1>;
				bypass = <0>;
				arqos = <0x4>;
				awqos = <0x4>;
				rmo = <0x10>;
				wmo = <0x8>;
				qurgent_on = <0>;
				blocking_on = <0>;
			};
			mfc_uhd_enc60 {
				stat_on = <1>;
				bypass = <0>;
				arqos = <0x4>;
				awqos = <0x4>;
				rmo = <0x8>;
				wmo = <0x8>;
				qurgent_on = <0>;
				blocking_on = <0>;
			};
			camera_heavy {
				stat_on = <1>;
				bypass = <0>;
				arqos = <0x4>;
				awqos = <0x4>;
				rmo = <0x20>;
				wmo = <0x20>;
				qurgent_on = <0>;
				blocking_on = <0>;
			};
			npu_performance {
				stat_on = <1>;
				bypass = <0>;
				arqos = <0x4>;
				awqos = <0x4>;
				rmo = <0x8>;
				wmo = <0x8>;
				qurgent_on = <0>;
				blocking_on = <0>;
			};
		};
		/* NOCL2A D1_MCFP */
		bts_mcfp1 {
			reg = <0x0 0x258E8480 0x80>;
			status = "okay";
			bts-type = <IP_BTS>;
			cal-pdid = <0xB1380002>;
			default {
				stat_on = <1>;
				bypass = <0>;
				arqos = <0x4>;
				awqos = <0x4>;
				rmo = <0x8>;
				wmo = <0x8>;
				qurgent_on = <0>;
				blocking_on = <0>;
			};
			camera_default {
				stat_on = <1>;
				bypass = <0>;
				arqos = <0x4>;
				awqos = <0x4>;
				rmo = <0x10>;
				wmo = <0x10>;
				qurgent_on = <0>;
				blocking_on = <0>;
			};
			npu_normal {
				stat_on = <1>;
				bypass = <0>;
				arqos = <0x4>;
				awqos = <0x4>;
				rmo = <0x10>;
				wmo = <0x10>;
				qurgent_on = <0>;
				blocking_on = <0>;
			};
			mfc_uhd_enc60 {
				stat_on = <1>;
				bypass = <0>;
				arqos = <0x4>;
				awqos = <0x4>;
				rmo = <0x8>;
				wmo = <0x8>;
				qurgent_on = <0>;
				blocking_on = <0>;
			};
			camera_heavy {
				stat_on = <1>;
				bypass = <0>;
				arqos = <0x4>;
				awqos = <0x4>;
				rmo = <0x20>;
				wmo = <0x20>;
				qurgent_on = <0>;
				blocking_on = <0>;
			};
			npu_performance {
				stat_on = <1>;
				bypass = <0>;
				arqos = <0x4>;
				awqos = <0x4>;
				rmo = <0x8>;
				wmo = <0x8>;
				qurgent_on = <0>;
				blocking_on = <0>;
			};
		};
		/* NOCL2A D2_MCFP */
		bts_mcfp2 {
			reg = <0x0 0x258E8500 0x80>;
			status = "okay";
			bts-type = <IP_BTS>;
			cal-pdid = <0xB1380002>;
			default {
				stat_on = <1>;
				bypass = <0>;
				arqos = <0x4>;
				awqos = <0x4>;
				rmo = <0x8>;
				wmo = <0x8>;
				qurgent_on = <0>;
				blocking_on = <0>;
			};
			camera_default {
				stat_on = <1>;
				bypass = <0>;
				arqos = <0x4>;
				awqos = <0x4>;
				rmo = <0x10>;
				wmo = <0x10>;
				qurgent_on = <0>;
				blocking_on = <0>;
			};
			npu_normal {
				stat_on = <1>;
				bypass = <0>;
				arqos = <0x4>;
				awqos = <0x4>;
				rmo = <0x10>;
				wmo = <0x10>;
				qurgent_on = <0>;
				blocking_on = <0>;
			};
			mfc_uhd_enc60 {
				stat_on = <1>;
				bypass = <0>;
				arqos = <0x4>;
				awqos = <0x4>;
				rmo = <0x8>;
				wmo = <0x8>;
				qurgent_on = <0>;
				blocking_on = <0>;
			};
			camera_heavy {
				stat_on = <1>;
				bypass = <0>;
				arqos = <0x4>;
				awqos = <0x4>;
				rmo = <0x20>;
				wmo = <0x20>;
				qurgent_on = <0>;
				blocking_on = <0>;
			};
			npu_performance {
				stat_on = <1>;
				bypass = <0>;
				arqos = <0x4>;
				awqos = <0x4>;
				rmo = <0x8>;
				wmo = <0x8>;
				qurgent_on = <0>;
				blocking_on = <0>;
			};
		};
		/* NOCL2A D3_MCFP */
		bts_mcfp3 {
			reg = <0x0 0x258E8580 0x80>;
			status = "okay";
			bts-type = <IP_BTS>;
			cal-pdid = <0xB1380002>;
			default {
				stat_on = <1>;
				bypass = <0>;
				arqos = <0x4>;
				awqos = <0x4>;
				rmo = <0x8>;
				wmo = <0x8>;
				qurgent_on = <0>;
				blocking_on = <0>;
			};
			camera_default {
				stat_on = <1>;
				bypass = <0>;
				arqos = <0x4>;
				awqos = <0x4>;
				rmo = <0x10>;
				wmo = <0x10>;
				qurgent_on = <0>;
				blocking_on = <0>;
			};
			npu_normal {
				stat_on = <1>;
				bypass = <0>;
				arqos = <0x4>;
				awqos = <0x4>;
				rmo = <0x10>;
				wmo = <0x10>;
				qurgent_on = <0>;
				blocking_on = <0>;
			};
			mfc_uhd_enc60 {
				stat_on = <1>;
				bypass = <0>;
				arqos = <0x4>;
				awqos = <0x4>;
				rmo = <0x8>;
				wmo = <0x8>;
				qurgent_on = <0>;
				blocking_on = <0>;
			};
			camera_heavy {
				stat_on = <1>;
				bypass = <0>;
				arqos = <0x4>;
				awqos = <0x4>;
				rmo = <0x20>;
				wmo = <0x20>;
				qurgent_on = <0>;
				blocking_on = <0>;
			};
			npu_performance {
				stat_on = <1>;
				bypass = <0>;
				arqos = <0x4>;
				awqos = <0x4>;
				rmo = <0x8>;
				wmo = <0x8>;
				qurgent_on = <0>;
				blocking_on = <0>;
			};
		};
		/* NOCL2A D4_MCFP */
		bts_mcfp4 {
			reg = <0x0 0x258E8600 0x80>;
			status = "okay";
			bts-type = <IP_BTS>;
			cal-pdid = <0xB1380002>;
			default {
				stat_on = <1>;
				bypass = <0>;
				arqos = <0x4>;
				awqos = <0x4>;
				rmo = <0x8>;
				wmo = <0x8>;
				qurgent_on = <0>;
				blocking_on = <0>;
			};
			camera_default {
				stat_on = <1>;
				bypass = <0>;
				arqos = <0x4>;
				awqos = <0x4>;
				rmo = <0x10>;
				wmo = <0x10>;
				qurgent_on = <0>;
				blocking_on = <0>;
			};
			npu_normal {
				stat_on = <1>;
				bypass = <0>;
				arqos = <0x4>;
				awqos = <0x4>;
				rmo = <0x10>;
				wmo = <0x10>;
				qurgent_on = <0>;
				blocking_on = <0>;
			};
			mfc_uhd_enc60 {
				stat_on = <1>;
				bypass = <0>;
				arqos = <0x4>;
				awqos = <0x4>;
				rmo = <0x8>;
				wmo = <0x8>;
				qurgent_on = <0>;
				blocking_on = <0>;
			};
			camera_heavy {
				stat_on = <1>;
				bypass = <0>;
				arqos = <0x4>;
				awqos = <0x4>;
				rmo = <0x20>;
				wmo = <0x20>;
				qurgent_on = <0>;
				blocking_on = <0>;
			};
			npu_performance {
				stat_on = <1>;
				bypass = <0>;
				arqos = <0x4>;
				awqos = <0x4>;
				rmo = <0x8>;
				wmo = <0x8>;
				qurgent_on = <0>;
				blocking_on = <0>;
			};
		};
		/* NOCL2A D0_YUVP */
		bts_yuvp0 {
			reg = <0x0 0x258E8680 0x80>;
			status = "okay";
			bts-type = <IP_BTS>;
			cal-pdid = <0xB1380002>;
			default {
				stat_on = <1>;
				bypass = <0>;
				arqos = <0x4>;
				awqos = <0x4>;
				rmo = <0xC>;
				wmo = <0xC>;
				qurgent_on = <0>;
				blocking_on = <0>;
			};
		};
		/* NOCL2A D1_YUVP */
		bts_yuvp1 {
			reg = <0x0 0x258E8700 0x80>;
			status = "okay";
			bts-type = <IP_BTS>;
			cal-pdid = <0xB1380002>;
			default {
				stat_on = <1>;
				bypass = <0>;
				arqos = <0x4>;
				awqos = <0x4>;
				rmo = <0xC>;
				wmo = <0xC>;
				qurgent_on = <0>;
				blocking_on = <0>;
			};
		};
		/* TREX_D_SDMA */
		/* D_sdma */
		bts_sdma0 {
			reg = <0x0 0x213F8000 0x80>;
			status = "okay";
			bts-type = <IP_BTS>;
			cal-pdid = <0xB1380019>;
			default {
				stat_on = <1>;
				bypass = <0>;
				arqos = <0x4>;
				awqos = <0x4>;
				rmo = <0xC>;
				wmo = <0xC>;
				qurgent_on = <0>;
				blocking_on = <0>;
			};
			camera_default {
				stat_on = <1>;
				bypass = <0>;
				arqos = <0x4>;
				awqos = <0x4>;
				rmo = <0x30>;
				wmo = <0x30>;
				qurgent_on = <0>;
				blocking_on = <0>;
			};
			npu_normal {
				stat_on = <1>;
				bypass = <0>;
				arqos = <0x4>;
				awqos = <0x4>;
				rmo = <0x50>;
				wmo = <0x50>;
				qurgent_on = <0>;
				blocking_on = <0>;
			};
			camera_heavy {
				stat_on = <1>;
				bypass = <0>;
				arqos = <0x4>;
				awqos = <0x4>;
				rmo = <0x50>;
				wmo = <0x50>;
				qurgent_on = <0>;
				blocking_on = <0>;
			};
			npu_performance {
				stat_on = <1>;
				bypass = <0>;
				arqos = <0x4>;
				awqos = <0x4>;
				rmo = <0xFFFF>;
				wmo = <0xFFFF>;
				qurgent_on = <0>;
				blocking_on = <0>;
			};
		};
		/* D_sdma */
		bts_sdma1 {
			reg = <0x0 0x213F8080 0x80>;
			status = "okay";
			bts-type = <IP_BTS>;
			cal-pdid = <0xB1380019>;
			default {
				stat_on = <1>;
				bypass = <0>;
				arqos = <0x4>;
				awqos = <0x4>;
				rmo = <0xC>;
				wmo = <0xC>;
				qurgent_on = <0>;
				blocking_on = <0>;
			};
			camera_default {
				stat_on = <1>;
				bypass = <0>;
				arqos = <0x4>;
				awqos = <0x4>;
				rmo = <0x30>;
				wmo = <0x30>;
				qurgent_on = <0>;
				blocking_on = <0>;
			};
			npu_normal {
				stat_on = <1>;
				bypass = <0>;
				arqos = <0x4>;
				awqos = <0x4>;
				rmo = <0x50>;
				wmo = <0x50>;
				qurgent_on = <0>;
				blocking_on = <0>;
			};
			camera_heavy {
				stat_on = <1>;
				bypass = <0>;
				arqos = <0x4>;
				awqos = <0x4>;
				rmo = <0x50>;
				wmo = <0x50>;
				qurgent_on = <0>;
				blocking_on = <0>;
			};
			npu_performance {
				stat_on = <1>;
				bypass = <0>;
				arqos = <0x4>;
				awqos = <0x4>;
				rmo = <0xFFFF>;
				wmo = <0xFFFF>;
				qurgent_on = <0>;
				blocking_on = <0>;
			};
		};
		/* D_sdma */
		bts_sdma2 {
			reg = <0x0 0x213F8100 0x80>;
			status = "okay";
			bts-type = <IP_BTS>;
			cal-pdid = <0xB1380019>;
			default {
				stat_on = <1>;
				bypass = <0>;
				arqos = <0x4>;
				awqos = <0x4>;
				rmo = <0xC>;
				wmo = <0xC>;
				qurgent_on = <0>;
				blocking_on = <0>;
			};
			camera_default {
				stat_on = <1>;
				bypass = <0>;
				arqos = <0x4>;
				awqos = <0x4>;
				rmo = <0x30>;
				wmo = <0x30>;
				qurgent_on = <0>;
				blocking_on = <0>;
			};
			npu_normal {
				stat_on = <1>;
				bypass = <0>;
				arqos = <0x4>;
				awqos = <0x4>;
				rmo = <0x50>;
				wmo = <0x50>;
				qurgent_on = <0>;
				blocking_on = <0>;
			};
			camera_heavy {
				stat_on = <1>;
				bypass = <0>;
				arqos = <0x4>;
				awqos = <0x4>;
				rmo = <0x50>;
				wmo = <0x50>;
				qurgent_on = <0>;
				blocking_on = <0>;
			};
			npu_performance {
				stat_on = <1>;
				bypass = <0>;
				arqos = <0x4>;
				awqos = <0x4>;
				rmo = <0xFFFF>;
				wmo = <0xFFFF>;
				qurgent_on = <0>;
				blocking_on = <0>;
			};
		};
		/* D_sdma */
		bts_sdma3 {
			reg = <0x0 0x213F8180 0x80>;
			status = "okay";
			bts-type = <IP_BTS>;
			cal-pdid = <0xB1380019>;
			default {
				stat_on = <1>;
				bypass = <0>;
				arqos = <0x4>;
				awqos = <0x4>;
				rmo = <0xC>;
				wmo = <0xC>;
				qurgent_on = <0>;
				blocking_on = <0>;
			};
			camera_default {
				stat_on = <1>;
				bypass = <0>;
				arqos = <0x4>;
				awqos = <0x4>;
				rmo = <0x30>;
				wmo = <0x30>;
				qurgent_on = <0>;
				blocking_on = <0>;
			};
			npu_normal {
				stat_on = <1>;
				bypass = <0>;
				arqos = <0x4>;
				awqos = <0x4>;
				rmo = <0x50>;
				wmo = <0x50>;
				qurgent_on = <0>;
				blocking_on = <0>;
			};
			camera_heavy {
				stat_on = <1>;
				bypass = <0>;
				arqos = <0x4>;
				awqos = <0x4>;
				rmo = <0x50>;
				wmo = <0x50>;
				qurgent_on = <0>;
				blocking_on = <0>;
			};
			npu_performance {
				stat_on = <1>;
				bypass = <0>;
				arqos = <0x4>;
				awqos = <0x4>;
				rmo = <0xFFFF>;
				wmo = <0xFFFF>;
				qurgent_on = <0>;
				blocking_on = <0>;
			};
		};
		/* D_sdma */
		bts_sdma4 {
			reg = <0x0 0x213F8200 0x80>;
			status = "okay";
			bts-type = <IP_BTS>;
			cal-pdid = <0xB1380019>;
			default {
				stat_on = <1>;
				bypass = <0>;
				arqos = <0x4>;
				awqos = <0x4>;
				rmo = <0xC>;
				wmo = <0xC>;
				qurgent_on = <0>;
				blocking_on = <0>;
			};
			camera_default {
				stat_on = <1>;
				bypass = <0>;
				arqos = <0x4>;
				awqos = <0x4>;
				rmo = <0x30>;
				wmo = <0x30>;
				qurgent_on = <0>;
				blocking_on = <0>;
			};
			npu_normal {
				stat_on = <1>;
				bypass = <0>;
				arqos = <0x4>;
				awqos = <0x4>;
				rmo = <0x50>;
				wmo = <0x50>;
				qurgent_on = <0>;
				blocking_on = <0>;
			};
			camera_heavy {
				stat_on = <1>;
				bypass = <0>;
				arqos = <0x4>;
				awqos = <0x4>;
				rmo = <0x50>;
				wmo = <0x50>;
				qurgent_on = <0>;
				blocking_on = <0>;
			};
			npu_performance {
				stat_on = <1>;
				bypass = <0>;
				arqos = <0x4>;
				awqos = <0x4>;
				rmo = <0xFFFF>;
				wmo = <0xFFFF>;
				qurgent_on = <0>;
				blocking_on = <0>;
			};
		};
		/* G3D CRPControl for MO and SYSREG_NOCL for QoS */
		bts_g3d0 {
			reg = <0x0 0x22800010 0x4>,	/* for MO */
			    <0x0 0x22821280 0x10>;	/* for QoS */
			status = "okay";
			bts-type = <SCI_GPU_BTS>;
			default {
				stat_on = <1>;
				bypass = <0>;
				arqos = <0x0>;
				awqos = <0x0>;
				rmo = <0x10>;
				wmo = <0x10>;
			};
			g3d_heavy {
				stat_on = <1>;
				bypass = <0>;
				arqos = <0x0>;
				awqos = <0x0>;
				rmo = <0x40>;
				wmo = <0x40>;
			};
			g3d_performance {
				stat_on = <1>;
				bypass = <0>;
				arqos = <0x0>;
				awqos = <0x0>;
				rmo = <0x40>;
				wmo = <0x40>;
			};
			camera_default {
				stat_on = <1>;
				bypass = <0>;
				arqos = <0x0>;
				awqos = <0x0>;
				rmo = <0x8>;
				wmo = <0x8>;
			};
			npu_normal {
				stat_on = <1>;
				bypass = <0>;
				arqos = <0x0>;
				awqos = <0x0>;
				rmo = <0x8>;
				wmo = <0x8>;
			};
			mfc_uhd_enc60 {
				stat_on = <1>;
				bypass = <0>;
				arqos = <0x0>;
				awqos = <0x0>;
				rmo = <0x8>;
				wmo = <0x8>;
			};
			camera_heavy {
				stat_on = <1>;
				bypass = <0>;
				arqos = <0x0>;
				awqos = <0x0>;
				rmo = <0x8>;
				wmo = <0x8>;
			};
			npu_performance {
				stat_on = <1>;
				bypass = <0>;
				arqos = <0x0>;
				awqos = <0x0>;
				rmo = <0x40>;
				wmo = <0x40>;
			};
		};
		bts_g3d1 {
			reg = <0x0 0x22800038 0x4>,	/* for MO */
			    <0x0 0x22821290 0x10>;	/* for QoS */
			status = "okay";
			bts-type = <SCI_GPU_BTS>;
			default {
				stat_on = <1>;
				bypass = <0>;
				arqos = <0x0>;
				awqos = <0x0>;
				rmo = <0x10>;
				wmo = <0x10>;
			};
			g3d_heavy {
				stat_on = <1>;
				bypass = <0>;
				arqos = <0x0>;
				awqos = <0x0>;
				rmo = <0x40>;
				wmo = <0x40>;
			};
			g3d_performance {
				stat_on = <1>;
				bypass = <0>;
				arqos = <0x0>;
				awqos = <0x0>;
				rmo = <0x40>;
				wmo = <0x40>;
			};
			camera_default {
				stat_on = <1>;
				bypass = <0>;
				arqos = <0x0>;
				awqos = <0x0>;
				rmo = <0x8>;
				wmo = <0x8>;
			};
			npu_normal {
				stat_on = <1>;
				bypass = <0>;
				arqos = <0x0>;
				awqos = <0x0>;
				rmo = <0x8>;
				wmo = <0x8>;
			};
			mfc_uhd_enc60 {
				stat_on = <1>;
				bypass = <0>;
				arqos = <0x0>;
				awqos = <0x0>;
				rmo = <0x8>;
				wmo = <0x8>;
			};
			camera_heavy {
				stat_on = <1>;
				bypass = <0>;
				arqos = <0x0>;
				awqos = <0x0>;
				rmo = <0x8>;
				wmo = <0x8>;
			};
			npu_performance {
				stat_on = <1>;
				bypass = <0>;
				arqos = <0x0>;
				awqos = <0x0>;
				rmo = <0x40>;
				wmo = <0x40>;
			};
		};
		bts_g3d2 {
			reg = <0x0 0x22800060 0x4>,	/* for MO */
			    <0x0 0x228212A0 0x10>;	/* for QoS */
			status = "okay";
			bts-type = <SCI_GPU_BTS>;
			default {
				stat_on = <1>;
				bypass = <0>;
				arqos = <0x0>;
				awqos = <0x0>;
				rmo = <0x10>;
				wmo = <0x10>;
			};
			g3d_heavy {
				stat_on = <1>;
				bypass = <0>;
				arqos = <0x0>;
				awqos = <0x0>;
				rmo = <0x40>;
				wmo = <0x40>;
			};
			g3d_performance {
				stat_on = <1>;
				bypass = <0>;
				arqos = <0x0>;
				awqos = <0x0>;
				rmo = <0x40>;
				wmo = <0x40>;
			};
			camera_default {
				stat_on = <1>;
				bypass = <0>;
				arqos = <0x0>;
				awqos = <0x0>;
				rmo = <0x8>;
				wmo = <0x8>;
			};
			npu_normal {
				stat_on = <1>;
				bypass = <0>;
				arqos = <0x0>;
				awqos = <0x0>;
				rmo = <0x8>;
				wmo = <0x8>;
			};
			mfc_uhd_enc60 {
				stat_on = <1>;
				bypass = <0>;
				arqos = <0x0>;
				awqos = <0x0>;
				rmo = <0x8>;
				wmo = <0x8>;
			};
			camera_heavy {
				stat_on = <1>;
				bypass = <0>;
				arqos = <0x0>;
				awqos = <0x0>;
				rmo = <0x8>;
				wmo = <0x8>;
			};
			npu_performance {
				stat_on = <1>;
				bypass = <0>;
				arqos = <0x0>;
				awqos = <0x0>;
				rmo = <0x40>;
				wmo = <0x40>;
			};
		};
		bts_g3d3 {
			reg = <0x0 0x22800088 0x4>,	/* for MO */
			    <0x0 0x228212B0 0x10>;	/* for QoS */
			status = "okay";
			bts-type = <SCI_GPU_BTS>;
			default {
				stat_on = <1>;
				bypass = <0>;
				arqos = <0x0>;
				awqos = <0x0>;
				rmo = <0x10>;
				wmo = <0x10>;
			};
			g3d_heavy {
				stat_on = <1>;
				bypass = <0>;
				arqos = <0x0>;
				awqos = <0x0>;
				rmo = <0x40>;
				wmo = <0x40>;
			};
			g3d_performance {
				stat_on = <1>;
				bypass = <0>;
				arqos = <0x0>;
				awqos = <0x0>;
				rmo = <0x40>;
				wmo = <0x40>;
			};
			camera_default {
				stat_on = <1>;
				bypass = <0>;
				arqos = <0x0>;
				awqos = <0x0>;
				rmo = <0x8>;
				wmo = <0x8>;
			};
			npu_normal {
				stat_on = <1>;
				bypass = <0>;
				arqos = <0x0>;
				awqos = <0x0>;
				rmo = <0x8>;
				wmo = <0x8>;
			};
			mfc_uhd_enc60 {
				stat_on = <1>;
				bypass = <0>;
				arqos = <0x0>;
				awqos = <0x0>;
				rmo = <0x8>;
				wmo = <0x8>;
			};
			camera_heavy {
				stat_on = <1>;
				bypass = <0>;
				arqos = <0x0>;
				awqos = <0x0>;
				rmo = <0x8>;
				wmo = <0x8>;
			};
			npu_performance {
				stat_on = <1>;
				bypass = <0>;
				arqos = <0x0>;
				awqos = <0x0>;
				rmo = <0x40>;
				wmo = <0x40>;
			};
		};
	};
};
